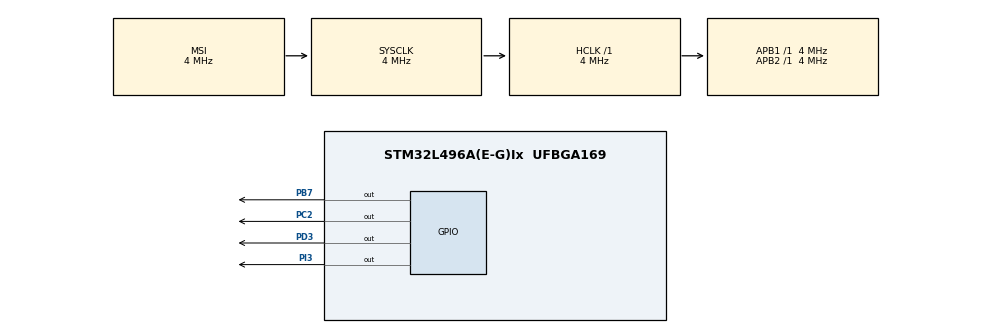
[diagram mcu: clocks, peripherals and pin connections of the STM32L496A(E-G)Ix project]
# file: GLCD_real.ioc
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Mcu.Family=STM32L4
Mcu.Name=STM32L496A(E-G)Ix
Mcu.Package=UFBGA169
NVIC.PriorityGroup=NVIC_PRIORITYGROUP_4
PA13\ (JTMS/SWDIO).Mode=Serial_Wire
PA13\ (JTMS/SWDIO).Signal=SYS_JTMS-SWDIO
PA14\ (JTCK/SWCLK).Mode=Serial_Wire
PA14\ (JTCK/SWCLK).Signal=SYS_JTCK-SWCLK
PB7.Signal=GPIO_Output
PC2.Signal=GPIO_Output
PD3.Signal=GPIO_Output
PI3.Signal=GPIO_Output
ProjectManager.HeapSize=0x200
ProjectManager.StackSize=0x400
ProjectManager.TargetToolchain=STM32CubeIDE
RCC.ADCFreq_Value=16000000
RCC.AHBFreq_Value=4000000
RCC.APB1Freq_Value=4000000
RCC.APB1TimFreq_Value=4000000
RCC.APB2Freq_Value=4000000
RCC.APB2TimFreq_Value=4000000
RCC.CortexFreq_Value=4000000
RCC.HCLKFreq_Value=4000000
RCC.HSE_VALUE=8000000
RCC.HSI48_VALUE=48000000
RCC.HSI_VALUE=16000000
RCC.LSE_VALUE=32768
RCC.MSI_VALUE=4000000
RCC.SYSCLKFreq_VALUE=4000000
RCC.USBFreq_Value=16000000
RCC.VCOOutputFreq_Value=32000000
TIM1.Period=0xffff-1
TIM1.Prescaler=71
VP_TIM1_VS_ClockSourceINT.Mode=Internal
board=custom

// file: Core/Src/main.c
/* USER CODE BEGIN Header */
/**
  ******************************************************************************
  * @file           : main.c
  * @brief          : Main program body
  ******************************************************************************
  * @attention
  *
  * Copyright (c) 2023 STMicroelectronics.
  * All rights reserved.
  *
  * This software is licensed under terms that can be found in the LICENSE file
  * in the root directory of this software component.
  * If no LICENSE file comes with this software, it is provided AS-IS.
  *
  ******************************************************************************
  */
/* USER CODE END Header */
#include "main.h"

/* USER CODE BEGIN Includes */
#include "ST7920_SERIAL.h"
#include "bitmap.h"
#include "delay.h"
/* USER CODE END Includes */

TIM_HandleTypeDef htim1;

void SystemClock_Config(void);
static void MX_GPIO_Init(void);
static void MX_TIM1_Init(void);

int main(void)
{

  /* MCU Configuration--------------------------------------------------------*/

  /* Reset of all peripherals, Initializes the Flash interface and the Systick. */
  HAL_Init();

  /* Configure the system clock */
  SystemClock_Config();

  /* Initialize all configured peripherals */
  MX_GPIO_Init();
  MX_TIM1_Init();
  /* USER CODE BEGIN 2 */
  delay_init();
  ST7920_Clear();
  ST7920_Init();
  ST7920_Clear();
  ST7920_GraphicMode(1);
  ST7920_Clear();
  Sendstring7_9GLCD(0,0,"012345");
  ST7920_Update();
//  Sendstring5_3GLCD(0, 0, "12:23");
//  ST7920_Update();
//  Sendstring5_3GLCD(88, 0, "15:01:1999");
//  ST7920_Update();
//  SendcharGLCD(8,3,'A');
//  SendcharGLCD(14,11,'B');
//  SendcharGLCD(20,3,'G');
//  SendstringGLCD(23, 5, "0123456789");
//  ST7920_Update();
//  HAL_Delay(2000);
//  	for(int x=0;x<8;x++)
//  	{
//  		SetPixel(x, 34);
//  		//ST7920_Update();
//  	}
//  	ST7920_Update();
//	for(int x=0;x<8;x++)
//  	{
//  		ClearPixel(x, 34);
//
//  	}
//	ST7920_Update();

//  ST7920_DrawBitmap(bitmap);
//  ST7920_Update();
//  ST7920_Clear();

//  ST7920_DrawBitmap(nhip_tim);

//  ST7920_Clear();
//  LCD_GraphicsDisplayString(1,"Blood Pressure");
//  LCD_GraphicsDisplayString(2,"Monitor V2");
//  ST7920_GraphicLCD_Font_Print(2,3," Nguyen");
//  ST7920_Update();
//  HAL_Delay(2000);
//  HAL_Delay(2000);
//  ST7920_Clear();
//  ST7920_DrawBitmap(logo);
//  HAL_Delay(2000);
//  ST7920_Clear();

//    HAL_Delay(5000);

//  ST7920_DrawBitmap(bitmap);
//  HAL_Delay(2000);
//  ST7920_DrawBitmap(logo);
//  HAL_Delay(2000);
//  ST7920_Update();
//  ST7920_Clear();

//  DrawCircle(110, 31, 12);
//
//  DrawCircle(110, 31, 16);
//
//  DrawLine(3, 60, 127, 33);
//
//  ST7920_Update();
//
//  DrawRectangle (0, 0, 122,62 );
//
//  ST7920_Update();
//
//  DrawLine(0,0,30,30);
//  ST7920_Update();

//
//  DrawFilledRectangle(30, 20, 30, 10);
//
//  ST7920_Update();
//
//  DrawFilledCircle(15, 30, 6);
//
//  ST7920_Update();
//
//  DrawFilledTriangle(1,5,10,5,6,15);
//
//  ST7920_Update();
//  ST7920_Clear();
  /* USER CODE END 2 */

  /* Infinite loop */
  while (1)
  {

  }
}

void SystemClock_Config(void)
{
  RCC_OscInitTypeDef RCC_OscInitStruct = {0};
  RCC_ClkInitTypeDef RCC_ClkInitStruct = {0};

  /** Configure the main internal regulator output voltage
  */
  if (HAL_PWREx_ControlVoltageScaling(PWR_REGULATOR_VOLTAGE_SCALE1) != HAL_OK)
  {
    Error_Handler();
  }

  /** Initializes the RCC Oscillators according to the specified parameters
  * in the RCC_OscInitTypeDef structure.
  */
  RCC_OscInitStruct.OscillatorType = RCC_OSCILLATORTYPE_MSI;
  RCC_OscInitStruct.MSIState = RCC_MSI_ON;
  RCC_OscInitStruct.MSICalibrationValue = 0;
  RCC_OscInitStruct.MSIClockRange = RCC_MSIRANGE_6;
  RCC_OscInitStruct.PLL.PLLState = RCC_PLL_NONE;
  if (HAL_RCC_OscConfig(&RCC_OscInitStruct) != HAL_OK)
  {
    Error_Handler();
  }

  /** Initializes the CPU, AHB and APB buses clocks
  */
  RCC_ClkInitStruct.ClockType = RCC_CLOCKTYPE_HCLK|RCC_CLOCKTYPE_SYSCLK
                              |RCC_CLOCKTYPE_PCLK1|RCC_CLOCKTYPE_PCLK2;
  RCC_ClkInitStruct.SYSCLKSource = RCC_SYSCLKSOURCE_MSI;
  RCC_ClkInitStruct.AHBCLKDivider = RCC_SYSCLK_DIV1;
  RCC_ClkInitStruct.APB1CLKDivider = RCC_HCLK_DIV1;
  RCC_ClkInitStruct.APB2CLKDivider = RCC_HCLK_DIV1;

  if (HAL_RCC_ClockConfig(&RCC_ClkInitStruct, FLASH_LATENCY_0) != HAL_OK)
  {
    Error_Handler();
  }
}

static void MX_TIM1_Init(void)
{

  TIM_ClockConfigTypeDef sClockSourceConfig = {0};
  TIM_MasterConfigTypeDef sMasterConfig = {0};

  htim1.Instance = TIM1;
  htim1.Init.Prescaler = 71;
  htim1.Init.CounterMode = TIM_COUNTERMODE_UP;
  htim1.Init.Period = 0xffff-1;
  htim1.Init.ClockDivision = TIM_CLOCKDIVISION_DIV1;
  htim1.Init.RepetitionCounter = 0;
  htim1.Init.AutoReloadPreload = TIM_AUTORELOAD_PRELOAD_DISABLE;
  if (HAL_TIM_Base_Init(&htim1) != HAL_OK)
  {
    Error_Handler();
  }
  sClockSourceConfig.ClockSource = TIM_CLOCKSOURCE_INTERNAL;
  if (HAL_TIM_ConfigClockSource(&htim1, &sClockSourceConfig) != HAL_OK)
  {
    Error_Handler();
  }
  sMasterConfig.MasterOutputTrigger = TIM_TRGO_RESET;
  sMasterConfig.MasterOutputTrigger2 = TIM_TRGO2_RESET;
  sMasterConfig.MasterSlaveMode = TIM_MASTERSLAVEMODE_DISABLE;
  if (HAL_TIMEx_MasterConfigSynchronization(&htim1, &sMasterConfig) != HAL_OK)
  {
    Error_Handler();
  }

}

static void MX_GPIO_Init(void)
{
  GPIO_InitTypeDef GPIO_InitStruct = {0};

  /* GPIO Ports Clock Enable */
  __HAL_RCC_GPIOA_CLK_ENABLE();
  __HAL_RCC_GPIOI_CLK_ENABLE();
  __HAL_RCC_GPIOB_CLK_ENABLE();
  __HAL_RCC_GPIOD_CLK_ENABLE();
  __HAL_RCC_GPIOC_CLK_ENABLE();

  /*Configure GPIO pin Output Level */
  HAL_GPIO_WritePin(GPIOI, GPIO_PIN_3, GPIO_PIN_RESET);

  /*Configure GPIO pin Output Level */
  HAL_GPIO_WritePin(GPIOB, GPIO_PIN_7, GPIO_PIN_RESET);

  /*Configure GPIO pin Output Level */
  HAL_GPIO_WritePin(GPIOD, GPIO_PIN_3, GPIO_PIN_RESET);

  /*Configure GPIO pin Output Level */
  HAL_GPIO_WritePin(GPIOC, GPIO_PIN_2, GPIO_PIN_RESET);

  /*Configure GPIO pin : PI3 */
  GPIO_InitStruct.Pin = GPIO_PIN_3;
  GPIO_InitStruct.Mode = GPIO_MODE_OUTPUT_PP;
  GPIO_InitStruct.Pull = GPIO_NOPULL;
  GPIO_InitStruct.Speed = GPIO_SPEED_FREQ_LOW;
  HAL_GPIO_Init(GPIOI, &GPIO_InitStruct);

  /*Configure GPIO pin : PB7 */
  GPIO_InitStruct.Pin = GPIO_PIN_7;
  GPIO_InitStruct.Mode = GPIO_MODE_OUTPUT_PP;
  GPIO_InitStruct.Pull = GPIO_NOPULL;
  GPIO_InitStruct.Speed = GPIO_SPEED_FREQ_LOW;
  HAL_GPIO_Init(GPIOB, &GPIO_InitStruct);

  /*Configure GPIO pin : PD3 */
  GPIO_InitStruct.Pin = GPIO_PIN_3;
  GPIO_InitStruct.Mode = GPIO_MODE_OUTPUT_PP;
  GPIO_InitStruct.Pull = GPIO_NOPULL;
  GPIO_InitStruct.Speed = GPIO_SPEED_FREQ_LOW;
  HAL_GPIO_Init(GPIOD, &GPIO_InitStruct);

  /*Configure GPIO pin : PC2 */
  GPIO_InitStruct.Pin = GPIO_PIN_2;
  GPIO_InitStruct.Mode = GPIO_MODE_OUTPUT_PP;
  GPIO_InitStruct.Pull = GPIO_NOPULL;
  GPIO_InitStruct.Speed = GPIO_SPEED_FREQ_LOW;
  HAL_GPIO_Init(GPIOC, &GPIO_InitStruct);

}

void Error_Handler(void)
{
  __disable_irq();
  while (1)
  {
  }
}
